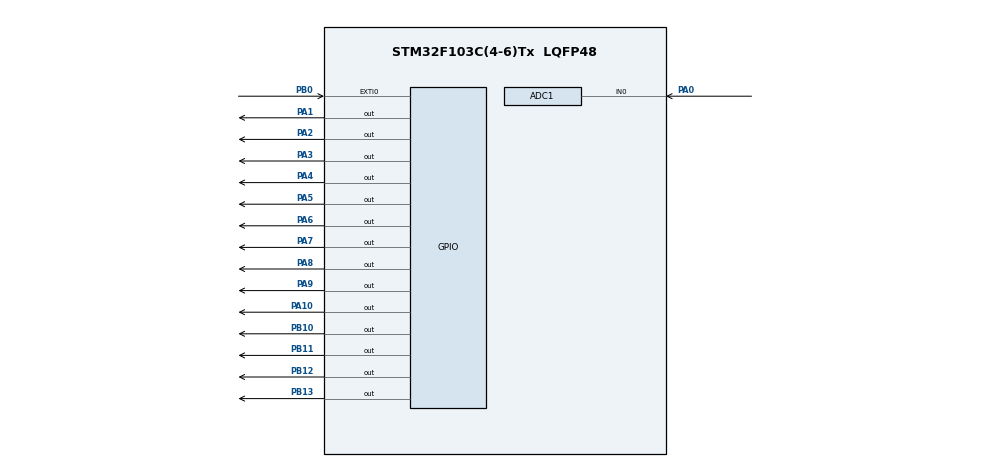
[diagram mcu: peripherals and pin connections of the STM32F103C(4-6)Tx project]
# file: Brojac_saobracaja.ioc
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ADC1.Channel-0\#ChannelRegularConversion=ADC_CHANNEL_0
ADC1.NbrOfConversionFlag=1
ADC1.Rank-0\#ChannelRegularConversion=1
ADC1.SamplingTime-0\#ChannelRegularConversion=ADC_SAMPLETIME_1CYCLE_5
ADC1.master=1
Mcu.Family=STM32F1
Mcu.Name=STM32F103C(4-6)Tx
Mcu.Package=LQFP48
NVIC.EXTI0_IRQn=true\:0\:0\:false\:false\:true\:true\:true\:true
NVIC.PriorityGroup=NVIC_PRIORITYGROUP_4
PA0-WKUP.Signal=ADCx_IN0
PA1.Signal=GPIO_Output
PA10.Signal=GPIO_Output
PA2.Signal=GPIO_Output
PA3.Signal=GPIO_Output
PA4.Signal=GPIO_Output
PA5.Signal=GPIO_Output
PA6.Signal=GPIO_Output
PA7.Signal=GPIO_Output
PA8.Signal=GPIO_Output
PA9.Signal=GPIO_Output
PB0.GPIO_ModeDefaultEXTI=GPIO_MODE_IT_FALLING
PB0.Signal=GPXTI0
PB10.Signal=GPIO_Output
PB11.Signal=GPIO_Output
PB12.Signal=GPIO_Output
PB13.Signal=GPIO_Output
ProjectManager.HeapSize=0x200
ProjectManager.StackSize=0x400
ProjectManager.TargetToolchain=STM32CubeIDE
RCC.APB1Freq_Value=8000000
RCC.APB2Freq_Value=8000000
SH.ADCx_IN0.0=ADC1_IN0,IN0
VP_SYS_VS_ND.Mode=No_Debug
board=custom

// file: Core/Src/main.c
/* USER CODE BEGIN Header */
/**
  ******************************************************************************
  * @file           : main.c
  * @brief          : Main program body
  ******************************************************************************
  * @attention
  *
  * Copyright (c) 2023 STMicroelectronics.
  * All rights reserved.
  *
  * This software is licensed under terms that can be found in the LICENSE file
  * in the root directory of this software component.
  * If no LICENSE file comes with this software, it is provided AS-IS.
  *
  ******************************************************************************
  */
/* USER CODE END Header */
#include "main.h"
#include "stdio.h"

/* USER CODE BEGIN Includes */
uint16_t vehicleCount = 0;
uint8_t simulationRunning = 0;
/* USER CODE END Includes */

ADC_HandleTypeDef hadc1;

void SystemClock_Config(void);
static void MX_GPIO_Init(void);
static void MX_ADC1_Init(void);

void LCD(uint8_t value, uint8_t command)
{
	uint8_t data;

	HAL_GPIO_WritePin(GPIOA, GPIO_PIN_8, command);

	data = value & 0x01;
	HAL_GPIO_WritePin(GPIOA, GPIO_PIN_10, data);

	data = (value >> 1) & 0x01;
	HAL_GPIO_WritePin(GPIOA, GPIO_PIN_1, data);

	data = (value >> 2) & 0x01;
	HAL_GPIO_WritePin(GPIOA, GPIO_PIN_2, data);

	data = (value >> 3) & 0x01;
	HAL_GPIO_WritePin(GPIOA, GPIO_PIN_3, data);

	data = (value >> 4) & 0x01;
	HAL_GPIO_WritePin(GPIOA, GPIO_PIN_4, data);

	data = (value >> 5) & 0x01;
	HAL_GPIO_WritePin(GPIOA, GPIO_PIN_5, data);

	data = (value >> 6) & 0x01;
	HAL_GPIO_WritePin(GPIOA, GPIO_PIN_6, data);

	data = (value >> 7) & 0x01;
	HAL_GPIO_WritePin(GPIOA, GPIO_PIN_7, data);

	HAL_GPIO_WritePin(GPIOA, GPIO_PIN_9, GPIO_PIN_SET);
	HAL_Delay(50);
	HAL_GPIO_WritePin(GPIOA, GPIO_PIN_9, GPIO_PIN_RESET);
}

void InitializeLCDScreen()
{
	LCD(0x38,0);
	LCD(0x0C,0);
	LCD(0x06,0);
	LCD(0x01,0);
	LCD(0x80,0);
}

void HAL_GPIO_EXTI_Callback(uint16_t GPIO_Pin)
{
	if (GPIO_Pin == GPIO_PIN_0)
	{
		simulationRunning = !simulationRunning;

	}
}

void turnOnGreenLED()
{
    HAL_GPIO_WritePin(GPIOB, GPIO_PIN_10, GPIO_PIN_RESET);
    HAL_GPIO_WritePin(GPIOB, GPIO_PIN_11, GPIO_PIN_SET);
    HAL_GPIO_WritePin(GPIOB, GPIO_PIN_12, GPIO_PIN_SET);
}

void turnOnRedLED()
{
    HAL_GPIO_WritePin(GPIOB, GPIO_PIN_10, GPIO_PIN_SET);
    HAL_GPIO_WritePin(GPIOB, GPIO_PIN_11, GPIO_PIN_RESET);
    HAL_GPIO_WritePin(GPIOB, GPIO_PIN_12, GPIO_PIN_SET);
}

void turnOnBlueLED()
{
    HAL_GPIO_WritePin(GPIOB, GPIO_PIN_10, GPIO_PIN_SET);
    HAL_GPIO_WritePin(GPIOB, GPIO_PIN_11, GPIO_PIN_SET);
    HAL_GPIO_WritePin(GPIOB, GPIO_PIN_12, GPIO_PIN_RESET);
}

void turnAllLEDsOff()
{
	 HAL_GPIO_WritePin(GPIOB, GPIO_PIN_10, GPIO_PIN_SET);
	 HAL_GPIO_WritePin(GPIOB, GPIO_PIN_11, GPIO_PIN_SET);
	 HAL_GPIO_WritePin(GPIOB, GPIO_PIN_12, GPIO_PIN_SET);
	 HAL_GPIO_WritePin(GPIOB, GPIO_PIN_13, GPIO_PIN_SET);
}

void updateVehicleCountLCD()
{
	InitializeLCDScreen();
    char buffer[16];
    snprintf(buffer, sizeof(buffer), "Vozila: %u", vehicleCount);
    LCD(0x01, 0);
    for (int i = 0; buffer[i]; i++) {
        LCD(buffer[i], 1);
    }
}

// Ova funkcija simulira prolazak u skladu sa naponom na potenciometru
void simulatePassage(uint32_t delay_time) {

	HAL_GPIO_WritePin(GPIOB, GPIO_PIN_13, GPIO_PIN_RESET);
    HAL_Delay(delay_time);
    HAL_GPIO_WritePin(GPIOB, GPIO_PIN_13, GPIO_PIN_SET);
}

int main(void)
{

  /* MCU Configuration--------------------------------------------------------*/

  /* Reset of all peripherals, Initializes the Flash interface and the Systick. */
  HAL_Init();

  /* Configure the system clock */
  SystemClock_Config();

  /* Initialize all configured peripherals */
  MX_GPIO_Init();
  MX_ADC1_Init();

  /* Infinite loop */
  /* USER CODE BEGIN WHILE */

  turnAllLEDsOff();
  InitializeLCDScreen();

  /* USER CODE END 3 */
    while (1) {
    		if (simulationRunning)
    		{
				HAL_ADC_Start(&hadc1);
				HAL_ADC_PollForConversion(&hadc1, HAL_MAX_DELAY);
				uint16_t potentiometer_value = HAL_ADC_GetValue(&hadc1);
				HAL_ADC_Stop(&hadc1);

				uint32_t delay_time = (potentiometer_value * 1000) / 4095;

				// Simuliramo prolazak vozila
				if (vehicleCount <= 10)
				{
					// Manje od 11 vozila je proslo
					turnOnGreenLED();

					vehicleCount++;
					updateVehicleCountLCD();

					simulatePassage(delay_time);
				}
				else if (vehicleCount >= 11 && vehicleCount <= 20)
				{
					// 20 - 50 vozila je proslo
					turnOnRedLED();

					vehicleCount++;
					updateVehicleCountLCD();

					simulatePassage(delay_time);
				}
				else
				{
					// Vise od 50 vozila je proslo
					turnOnBlueLED();

					vehicleCount++;
					updateVehicleCountLCD();

					simulatePassage(delay_time);
				}
    		}
    		else
    		{
    			// Sistem je iskljucen
    			InitializeLCDScreen();
    			char buffer[16];
    			snprintf(buffer, sizeof(buffer), "ISKLJUCENO!");
    			LCD(0x01, 0);
    			for (int i = 0; buffer[i]; i++)
    			{
    				LCD(buffer[i], 1);
    			}
    			vehicleCount = 0;
    		    turnAllLEDsOff();
    		}
        }
}

void SystemClock_Config(void)
{
  RCC_OscInitTypeDef RCC_OscInitStruct = {0};
  RCC_ClkInitTypeDef RCC_ClkInitStruct = {0};
  RCC_PeriphCLKInitTypeDef PeriphClkInit = {0};

  /** Initializes the RCC Oscillators according to the specified parameters
  * in the RCC_OscInitTypeDef structure.
  */
  RCC_OscInitStruct.OscillatorType = RCC_OSCILLATORTYPE_HSI;
  RCC_OscInitStruct.HSIState = RCC_HSI_ON;
  RCC_OscInitStruct.HSICalibrationValue = RCC_HSICALIBRATION_DEFAULT;
  RCC_OscInitStruct.PLL.PLLState = RCC_PLL_NONE;
  if (HAL_RCC_OscConfig(&RCC_OscInitStruct) != HAL_OK)
  {
    Error_Handler();
  }

  /** Initializes the CPU, AHB and APB buses clocks
  */
  RCC_ClkInitStruct.ClockType = RCC_CLOCKTYPE_HCLK|RCC_CLOCKTYPE_SYSCLK
                              |RCC_CLOCKTYPE_PCLK1|RCC_CLOCKTYPE_PCLK2;
  RCC_ClkInitStruct.SYSCLKSource = RCC_SYSCLKSOURCE_HSI;
  RCC_ClkInitStruct.AHBCLKDivider = RCC_SYSCLK_DIV1;
  RCC_ClkInitStruct.APB1CLKDivider = RCC_HCLK_DIV1;
  RCC_ClkInitStruct.APB2CLKDivider = RCC_HCLK_DIV1;

  if (HAL_RCC_ClockConfig(&RCC_ClkInitStruct, FLASH_LATENCY_0) != HAL_OK)
  {
    Error_Handler();
  }
  PeriphClkInit.PeriphClockSelection = RCC_PERIPHCLK_ADC;
  PeriphClkInit.AdcClockSelection = RCC_ADCPCLK2_DIV2;
  if (HAL_RCCEx_PeriphCLKConfig(&PeriphClkInit) != HAL_OK)
  {
    Error_Handler();
  }
}

static void MX_ADC1_Init(void)
{

  ADC_ChannelConfTypeDef sConfig = {0};

  /** Common config
  */
  hadc1.Instance = ADC1;
  hadc1.Init.ScanConvMode = ADC_SCAN_DISABLE;
  hadc1.Init.ContinuousConvMode = ENABLE;
  hadc1.Init.DiscontinuousConvMode = DISABLE;
  hadc1.Init.ExternalTrigConv = ADC_SOFTWARE_START;
  hadc1.Init.DataAlign = ADC_DATAALIGN_RIGHT;
  hadc1.Init.NbrOfConversion = 1;
  if (HAL_ADC_Init(&hadc1) != HAL_OK)
  {
    Error_Handler();
  }

  /** Configure Regular Channel
  */
  sConfig.Channel = ADC_CHANNEL_0;
  sConfig.Rank = ADC_REGULAR_RANK_1;
  sConfig.SamplingTime = ADC_SAMPLETIME_1CYCLE_5;
  if (HAL_ADC_ConfigChannel(&hadc1, &sConfig) != HAL_OK)
  {
    Error_Handler();
  }

}

static void MX_GPIO_Init(void)
{
  GPIO_InitTypeDef GPIO_InitStruct = {0};

  /* GPIO Ports Clock Enable */
  __HAL_RCC_GPIOA_CLK_ENABLE();
  __HAL_RCC_GPIOB_CLK_ENABLE();

  /*Configure GPIO pin Output Level */
  HAL_GPIO_WritePin(GPIOA, GPIO_PIN_1|GPIO_PIN_2|GPIO_PIN_3|GPIO_PIN_4
                          |GPIO_PIN_5|GPIO_PIN_6|GPIO_PIN_7|GPIO_PIN_8
                          |GPIO_PIN_9|GPIO_PIN_10, GPIO_PIN_RESET);

  /*Configure GPIO pin Output Level */
  HAL_GPIO_WritePin(GPIOB, GPIO_PIN_10|GPIO_PIN_11|GPIO_PIN_12|GPIO_PIN_13, GPIO_PIN_SET);

  /*Configure GPIO pins : PA1 PA2 PA3 PA4
                           PA5 PA6 PA7 PA8
                           PA9 PA10 */
  GPIO_InitStruct.Pin = GPIO_PIN_1|GPIO_PIN_2|GPIO_PIN_3|GPIO_PIN_4
                          |GPIO_PIN_5|GPIO_PIN_6|GPIO_PIN_7|GPIO_PIN_8
                          |GPIO_PIN_9|GPIO_PIN_10;
  GPIO_InitStruct.Mode = GPIO_MODE_OUTPUT_PP;
  GPIO_InitStruct.Pull = GPIO_NOPULL;
  GPIO_InitStruct.Speed = GPIO_SPEED_FREQ_LOW;
  HAL_GPIO_Init(GPIOA, &GPIO_InitStruct);

  /*Configure GPIO pin : PB0 */
  GPIO_InitStruct.Pin = GPIO_PIN_0;
  GPIO_InitStruct.Mode = GPIO_MODE_IT_RISING;
  GPIO_InitStruct.Pull = GPIO_NOPULL;
  HAL_GPIO_Init(GPIOB, &GPIO_InitStruct);

  /*Configure GPIO pins : PB10 PB11 */
  GPIO_InitStruct.Pin = GPIO_PIN_10|GPIO_PIN_11|GPIO_PIN_12|GPIO_PIN_13;
  GPIO_InitStruct.Mode = GPIO_MODE_OUTPUT_PP;
  GPIO_InitStruct.Pull = GPIO_NOPULL;
  GPIO_InitStruct.Speed = GPIO_SPEED_FREQ_LOW;
  HAL_GPIO_Init(GPIOB, &GPIO_InitStruct);

  /* EXTI interrupt init*/
  HAL_NVIC_SetPriority(EXTI0_IRQn, 0, 0);
  HAL_NVIC_EnableIRQ(EXTI0_IRQn);

}

void Error_Handler(void)
{
  __disable_irq();
  while (1)
  {
  }
}
